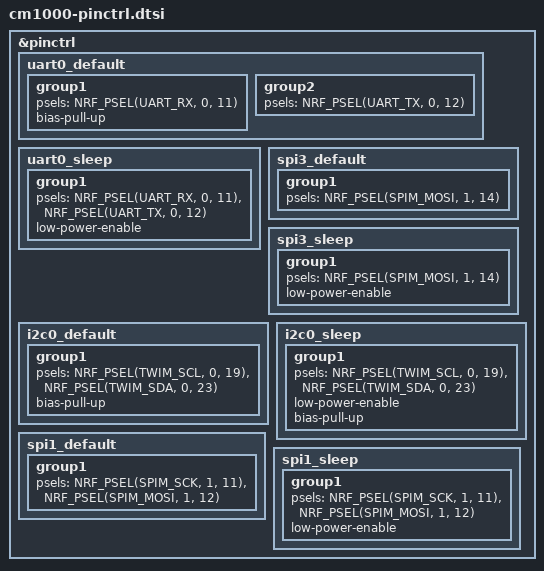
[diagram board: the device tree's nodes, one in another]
#include <dt-bindings/pinctrl/nrf-pinctrl.h>

&pinctrl {
    uart0_default: uart0_default {
        group1 {
            psels = <NRF_PSEL(UART_RX, 0, 11)>;
            bias-pull-up;
        };
        group2 {
            psels = <NRF_PSEL(UART_TX, 0, 12)>;
        };
    };

    uart0_sleep: uart0_sleep {
        group1 {
            psels = <NRF_PSEL(UART_RX, 0, 11)>,
                    <NRF_PSEL(UART_TX, 0, 12)>;
            low-power-enable;
        };
    };

    spi3_default: spi3_default {
        group1 {
            psels = <NRF_PSEL(SPIM_MOSI, 1, 14)>;
        };
    };

    spi3_sleep: spi3_sleep {
        group1 {
            psels = <NRF_PSEL(SPIM_MOSI, 1, 14)>;
            low-power-enable;
        };
    };

    i2c0_default: i2c0_default {
        group1 {
            psels = <NRF_PSEL(TWIM_SCL, 0, 19)>,
                    <NRF_PSEL(TWIM_SDA, 0, 23)>;
            bias-pull-up;
        };
    };

    i2c0_sleep: i2c0_sleep {
        group1 {
            psels = <NRF_PSEL(TWIM_SCL, 0, 19)>,
                    <NRF_PSEL(TWIM_SDA, 0, 23)>;
            low-power-enable;
            bias-pull-up;
        };
    };
};

&pinctrl {
    spi1_default: spi1_default {
        group1 {
            psels = <NRF_PSEL(SPIM_SCK, 1, 11)>,
                    <NRF_PSEL(SPIM_MOSI, 1, 12)>;
        };
    };
    spi1_sleep: spi1_sleep {
        group1 {
            psels = <NRF_PSEL(SPIM_SCK, 1, 11)>,
                    <NRF_PSEL(SPIM_MOSI, 1, 12)>;
            low-power-enable;
        };
    };
};
